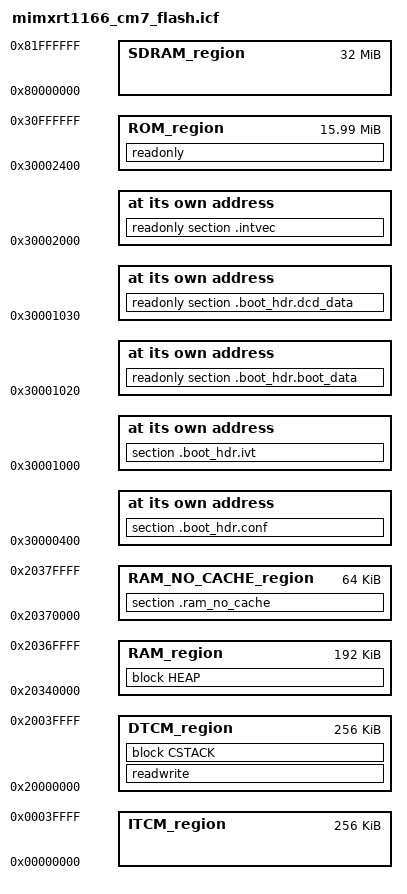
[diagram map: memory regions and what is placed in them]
/*###ICF### Section handled by ICF editor, don't touch! ****/
/*-Editor annotation file-*/
/* IcfEditorFile="$TOOLKIT_DIR$\config\ide\IcfEditor\cortex_v1_0.xml" */
/*-Specials-*/
define symbol __ICFEDIT_intvec_start__ = 0x30002000;
/*-Memory Regions-*/
define symbol __ICFEDIT_region_ROM_start__          = 0x30002400;
define symbol __ICFEDIT_region_ROM_end__            = 0x30FFFFFF;
define symbol __ICFEDIT_region_RAM_start__          = 0x20340000;
define symbol __ICFEDIT_region_RAM_end__            = 0x2036FFFF;
define symbol __ICFEDIT_region_RAM_NO_CACHE_start__ = 0x20370000;
define symbol __ICFEDIT_region_RAM_NO_CACHE_end__   = 0x2037FFFF;
define symbol __ICFEDIT_region_ITCM_start__         = 0x00000000;
define symbol __ICFEDIT_region_ITCM_end__           = 0x0003FFFF;
define symbol __ICFEDIT_region_DTCM_start__         = 0x20000000;
define symbol __ICFEDIT_region_DTCM_end__           = 0x2003FFFF;
define symbol __ICFEDIT_region_SDRAM_start__        = 0x80000000;
define symbol __ICFEDIT_region_SDRAM_end__          = 0x81FFFFFF;
/*-Sizes-*/
define symbol __ICFEDIT_size_cstack__ = 0x800;
define symbol __ICFEDIT_size_heap__   = 0x30000;
/**** End of ICF editor section. ###ICF###*/

define exported symbol m_boot_hdr_conf_start = 0x30000400;
define symbol m_boot_hdr_ivt_start           = 0x30001000;
define symbol m_boot_hdr_boot_data_start     = 0x30001020;
define symbol m_boot_hdr_dcd_data_start      = 0x30001030;

define exported symbol __VECTOR_TABLE  = __ICFEDIT_intvec_start__;
define exported symbol __VECTOR_RAM    = __ICFEDIT_intvec_start__;
define exported symbol __RAM_VECTOR_TABLE_SIZE = 0x0;

define memory mem with size  = 4G;
define region ROM_region          = mem:[from __ICFEDIT_region_ROM_start__          to __ICFEDIT_region_ROM_end__];
define region RAM_region          = mem:[from __ICFEDIT_region_RAM_start__          to __ICFEDIT_region_RAM_end__];
define region RAM_NO_CACHE_region = mem:[from __ICFEDIT_region_RAM_NO_CACHE_start__ to __ICFEDIT_region_RAM_NO_CACHE_end__];
define region ITCM_region         = mem:[from __ICFEDIT_region_ITCM_start__         to __ICFEDIT_region_ITCM_end__];
define region DTCM_region         = mem:[from __ICFEDIT_region_DTCM_start__         to __ICFEDIT_region_DTCM_end__];
define region SDRAM_region        = mem:[from __ICFEDIT_region_SDRAM_start__        to __ICFEDIT_region_SDRAM_end__];

define block CSTACK with alignment = 8, size = __ICFEDIT_size_cstack__   { };
define block HEAP   with alignment = 8, size = __ICFEDIT_size_heap__     { };

initialize by copy { readwrite };
do not initialize  { section .noinit };

place at address mem:__ICFEDIT_intvec_start__ { readonly section .intvec };

place at address mem:m_boot_hdr_conf_start { section .boot_hdr.conf };
place at address mem:m_boot_hdr_ivt_start { section .boot_hdr.ivt };
place at address mem:m_boot_hdr_boot_data_start { readonly section .boot_hdr.boot_data };
place at address mem:m_boot_hdr_dcd_data_start { readonly section .boot_hdr.dcd_data };

keep{ section .boot_hdr.conf, section .boot_hdr.ivt, section .boot_hdr.boot_data, section .boot_hdr.dcd_data };

place in ROM_region { readonly };
place in DTCM_region { readwrite, block CSTACK };
place in RAM_NO_CACHE_region { section .ram_no_cache };
place in RAM_region { block HEAP };
